# CC2753 register map
File version: 1.0
CPU: CM0+ r0p4, little endian, no MPU, no FPU, VTOR, 3 interrupt priority bits
Registers are 32-bit, read-write, reset 0x0 unless marked. A register's access mark holds for its fields unless they carry their own. Offsets are from the block's base; [hi:lo] are bit positions; {n}, {i} and the like mark numbered series; 'fields as' and 'values as' point back to an identical list.

## LRFDRFE32 (part 1 of 2)
Base 0x40083400
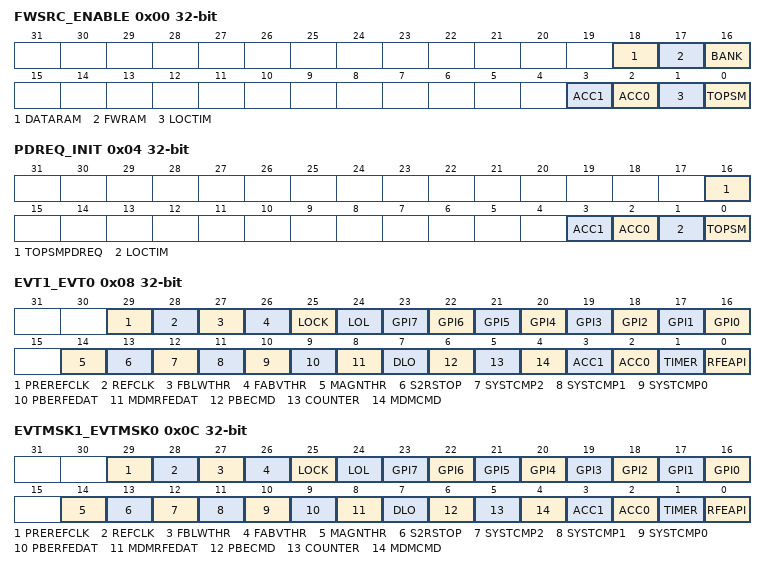
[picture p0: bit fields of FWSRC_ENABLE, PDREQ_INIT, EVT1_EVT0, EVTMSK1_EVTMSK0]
0x00 FWSRC_ENABLE — Internal. Only to be used through TI provided API.
  [18] DATARAM — Internal. Only to be used through TI provided API.
    1=S2RRAM (Internal. Only to be used through TI provided API.); 0=RFERAM (Internal. Only to be used through TI provided API.)
  [17] FWRAM — Internal. Only to be used through TI provided API.
    values as DATARAM
  [16] BANK — Internal. Only to be used through TI provided API.
    1=ONE (Internal. Only to be used through TI provided API.); 0=ZERO (Internal. Only to be used through TI provided API.)
  [3] ACC1 — Internal. Only to be used through TI provided API.
    1=EN (Internal. Only to be used through TI provided API.); 0=DIS (Internal. Only to be used through TI provided API.)
  [2] ACC0 — Internal. Only to be used through TI provided API.
    values as ACC1
  [1] LOCTIM — Internal. Only to be used through TI provided API.
    values as ACC1
  [0] TOPSM — Internal. Only to be used through TI provided API.
    values as ACC1
0x04 PDREQ_INIT wo — Internal. Only to be used through TI provided API.
  [16] TOPSMPDREQ — Internal. Only to be used through TI provided API.
    values as FWSRC_ENABLE.BANK
  [3] ACC1 — Internal. Only to be used through TI provided API.
    1=RESET (Internal. Only to be used through TI provided API.); 0=NO_EFFECT (Internal. Only to be used through TI provided API.)
  [2] ACC0 — Internal. Only to be used through TI provided API.
    values as ACC1
  [1] LOCTIM — Internal. Only to be used through TI provided API.
    values as ACC1
  [0] TOPSM — Internal. Only to be used through TI provided API.
    values as ACC1
0x08 EVT1_EVT0 ro — Internal. Only to be used through TI provided API.
  [all] fields
    values as FWSRC_ENABLE.BANK
  [29] PREREFCLK — Internal. Only to be used through TI provided API.
  [28] REFCLK — Internal. Only to be used through TI provided API.
  [27] FBLWTHR — Internal. Only to be used through TI provided API.
  [26] FABVTHR — Internal. Only to be used through TI provided API.
  [25] LOCK — Internal. Only to be used through TI provided API.
  [24] LOL — Internal. Only to be used through TI provided API.
  [n+16] GPI{n} (n=0..7) — Internal. Only to be used through TI provided API.
  [14] MAGNTHR — Internal. Only to be used through TI provided API.
  [13] S2RSTOP — Internal. Only to be used through TI provided API.
  [12] SYSTCMP2 — Internal. Only to be used through TI provided API.
  [11] SYSTCMP1 — Internal. Only to be used through TI provided API.
  [10] SYSTCMP0 — Internal. Only to be used through TI provided API.
  [9] PBERFEDAT — Internal. Only to be used through TI provided API.
  [8] MDMRFEDAT — Internal. Only to be used through TI provided API.
  [7] DLO — Internal. Only to be used through TI provided API.
  [6] PBECMD — Internal. Only to be used through TI provided API.
  [5] COUNTER — Internal. Only to be used through TI provided API.
  [4] MDMCMD — Internal. Only to be used through TI provided API.
  [3] ACC1 — Internal. Only to be used through TI provided API.
  [2] ACC0 — Internal. Only to be used through TI provided API.
  [1] TIMER — Internal. Only to be used through TI provided API.
  [0] RFEAPI — Internal. Only to be used through TI provided API.
0x0C EVTMSK1_EVTMSK0 — Internal. Only to be used through TI provided API.
  [all] fields
    values as FWSRC_ENABLE.ACC1
  [29] PREREFCLK — Internal. Only to be used through TI provided API.
  [28] REFCLK — Internal. Only to be used through TI provided API.
  [27] FBLWTHR — Internal. Only to be used through TI provided API.
  [26] FABVTHR — Internal. Only to be used through TI provided API.
  [25] LOCK — Internal. Only to be used through TI provided API.
  [24] LOL — Internal. Only to be used through TI provided API.
  [n+16] GPI{n} (n=0..7) — Internal. Only to be used through TI provided API.
  [14] MAGNTHR — Internal. Only to be used through TI provided API.
  [13] S2RSTOP — Internal. Only to be used through TI provided API.
  [12] SYSTCMP2 — Internal. Only to be used through TI provided API.
  [11] SYSTCMP1 — Internal. Only to be used through TI provided API.
  [10] SYSTCMP0 — Internal. Only to be used through TI provided API.
  [9] PBERFEDAT — Internal. Only to be used through TI provided API.
  [8] MDMRFEDAT — Internal. Only to be used through TI provided API.
  [7] DLO — Internal. Only to be used through TI provided API.
  [6] PBECMD — Internal. Only to be used through TI provided API.
  [5] COUNTER — Internal. Only to be used through TI provided API.
  [4] MDMCMD — Internal. Only to be used through TI provided API.
  [3] ACC1 — Internal. Only to be used through TI provided API.
  [2] ACC0 — Internal. Only to be used through TI provided API.
  [1] TIMER — Internal. Only to be used through TI provided API.
  [0] RFEAPI — Internal. Only to be used through TI provided API.
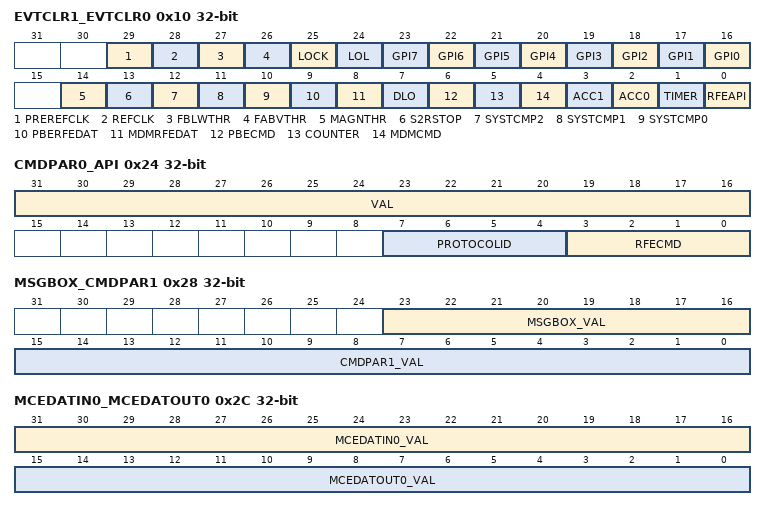
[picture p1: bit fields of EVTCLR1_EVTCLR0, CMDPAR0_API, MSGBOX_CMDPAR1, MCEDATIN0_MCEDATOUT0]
0x10 EVTCLR1_EVTCLR0 wo — Internal. Only to be used through TI provided API.
  fields as EVT1_EVT0
0x14 HFXTSTAT ro — Internal. Only to be used through TI provided API.
  [0] STAT
    1=QUAL (Internal. Only to be used through TI provided API.); 0=NONQUAL (Internal. Only to be used through TI provided API.)
0x18 RFSTATE — Internal. Only to be used through TI provided API.
  [3:0] VAL
    3=RX (Internal. Only to be used through TI provided API.); 2=TX (Internal. Only to be used through TI provided API.); 1=SYNTH (Internal. Only to be used through TI provided API.); 0=IDLE (Internal. Only to be used through TI provided API.)
0x24 CMDPAR0_API ro — Internal. Only to be used through TI provided API.
  [31:16] VAL — Internal. Only to be used through TI provided API.
    0xFFFF=ALLONES (Internal. Only to be used through TI provided API.); 0=ALLZEROS (Internal. Only to be used through TI provided API.)
  [7:4] PROTOCOLID — Internal. Only to be used through TI provided API.
    15=ALLONES (Internal. Only to be used through TI provided API.); 0=ALLZEROS (Internal. Only to be used through TI provided API.)
  [3:0] RFECMD — Internal. Only to be used through TI provided API.
    values as PROTOCOLID
0x28 MSGBOX_CMDPAR1 ro — Internal. Only to be used through TI provided API.
  [23:16] MSGBOX_VAL — Internal. Only to be used through TI provided API.
    255=ALLONES (Internal. Only to be used through TI provided API.); 0=ALLZEROS (Internal. Only to be used through TI provided API.)
  [15:0] CMDPAR1_VAL — Internal. Only to be used through TI provided API.
    values as CMDPAR0_API.VAL
0x2C MCEDATIN0_MCEDATOUT0 — Internal. Only to be used through TI provided API.
  [31:16] MCEDATIN0_VAL ro — Internal. Only to be used through TI provided API.
    values as CMDPAR0_API.VAL
  [15:0] MCEDATOUT0_VAL — Internal. Only to be used through TI provided API.
    values as CMDPAR0_API.VAL
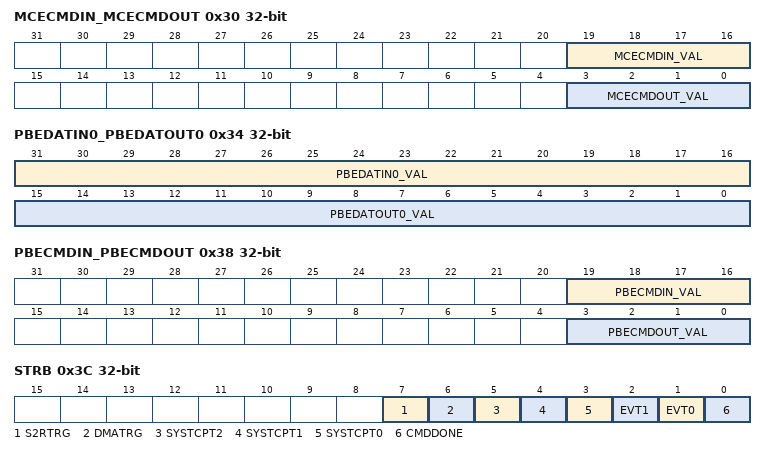
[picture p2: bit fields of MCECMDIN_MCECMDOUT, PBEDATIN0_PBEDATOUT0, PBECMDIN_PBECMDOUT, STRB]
0x30 MCECMDIN_MCECMDOUT — Internal. Only to be used through TI provided API.
  [19:16] MCECMDIN_VAL ro — Internal. Only to be used through TI provided API.
    values as CMDPAR0_API.PROTOCOLID
  [3:0] MCECMDOUT_VAL — Internal. Only to be used through TI provided API.
    values as CMDPAR0_API.PROTOCOLID
0x34 PBEDATIN0_PBEDATOUT0 — Internal. Only to be used through TI provided API.
  [31:16] PBEDATIN0_VAL ro — Internal. Only to be used through TI provided API.
    values as CMDPAR0_API.VAL
  [15:0] PBEDATOUT0_VAL — Internal. Only to be used through TI provided API.
    values as CMDPAR0_API.VAL
0x38 PBECMDIN_PBECMDOUT — Internal. Only to be used through TI provided API.
  [19:16] PBECMDIN_VAL ro — Internal. Only to be used through TI provided API.
    values as CMDPAR0_API.PROTOCOLID
  [3:0] PBECMDOUT_VAL — Internal. Only to be used through TI provided API.
    values as CMDPAR0_API.PROTOCOLID
0x3C STRB wo — Internal. Only to be used through TI provided API.
  [7] S2RTRG — Internal. Only to be used through TI provided API.
    values as FWSRC_ENABLE.BANK
  [6] DMATRG — Internal. Only to be used through TI provided API.
    values as FWSRC_ENABLE.BANK
  [5] SYSTCPT2 — Internal. Only to be used through TI provided API.
    values as FWSRC_ENABLE.BANK
  [4] SYSTCPT1 — Internal. Only to be used through TI provided API.
    values as FWSRC_ENABLE.BANK
  [3] SYSTCPT0 — Internal. Only to be used through TI provided API.
    values as FWSRC_ENABLE.BANK
  [2] EVT1 — Internal. Only to be used through TI provided API.
    values as FWSRC_ENABLE.BANK
  [1] EVT0 — Internal. Only to be used through TI provided API.
    values as FWSRC_ENABLE.BANK
  [0] CMDDONE — Internal. Only to be used through TI provided API.
    1=YES (Internal. Only to be used through TI provided API.); 0=NO (Internal. Only to be used through TI provided API.)
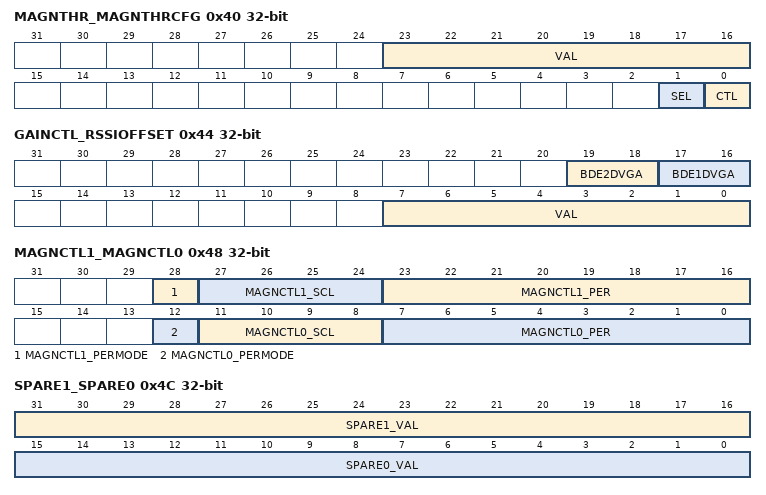
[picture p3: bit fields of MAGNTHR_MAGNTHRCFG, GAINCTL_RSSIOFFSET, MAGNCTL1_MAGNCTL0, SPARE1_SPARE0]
0x40 MAGNTHR_MAGNTHRCFG — Internal. Only to be used through TI provided API.
  [23:16] VAL — Internal. Only to be used through TI provided API.
    values as MSGBOX_CMDPAR1.MSGBOX_VAL
  [1] SEL — Internal. Only to be used through TI provided API.
    1=MAGNACC1 (Internal. Only to be used through TI provided API.); 0=MAGNACC0 (Internal. Only to be used through TI provided API.)
  [0] CTL — Internal. Only to be used through TI provided API.
    values as FWSRC_ENABLE.ACC1
0x44 GAINCTL_RSSIOFFSET — Internal. Only to be used through TI provided API.
  [19:18] BDE2DVGA — Internal. Only to be used through TI provided API.
    3=GAIN8 (Internal. Only to be used through TI provided API.); 2=GAIN4 (Internal. Only to be used through TI provided API.); 1=GAIN2 (Internal. Only to be used through TI provided API.); 0=GAIN1 (Internal. Only to be used through TI provided API.)
  [17:16] BDE1DVGA — Internal. Only to be used through TI provided API.
    values as BDE2DVGA
  [7:0] VAL — Internal. Only to be used through TI provided API.
    values as MSGBOX_CMDPAR1.MSGBOX_VAL
0x48 MAGNCTL1_MAGNCTL0 — Internal. Only to be used through TI provided API.
  [28] MAGNCTL1_PERMODE — Internal. Only to be used through TI provided API.
    1=PERIODIC (Internal. Only to be used through TI provided API.); 0=ONESHOT (Internal. Only to be used through TI provided API.)
  [27:24] MAGNCTL1_SCL — Internal. Only to be used through TI provided API.
    8=DIV256 (Internal. Only to be used through TI provided API.); 7=DIV128 (Internal. Only to be used through TI provided API.); 6=DIV64 (Internal. Only to be used through TI provided API.); 5=DIV32 (Internal. Only to be used through TI provided API.); 4=DIV16 (Internal. Only to be used through TI provided API.); 3=DIV8 (Internal. Only to be used through TI provided API.); 2=DIV4 (Internal. Only to be used through TI provided API.); 1=DIV2 (Internal. Only to be used through TI provided API.); 0=DIV1 (Internal. Only to be used through TI provided API.)
  [23:16] MAGNCTL1_PER — Internal. Only to be used through TI provided API.
    values as MSGBOX_CMDPAR1.MSGBOX_VAL
  [12] MAGNCTL0_PERMODE — Internal. Only to be used through TI provided API.
    values as MAGNCTL1_PERMODE
  [11:8] MAGNCTL0_SCL — Internal. Only to be used through TI provided API.
    values as MAGNCTL1_SCL
  [7:0] MAGNCTL0_PER — Internal. Only to be used through TI provided API.
    values as MSGBOX_CMDPAR1.MSGBOX_VAL
0x4C SPARE1_SPARE0 — Internal. Only to be used through TI provided API.
  [31:16] SPARE1_VAL — Internal. Only to be used through TI provided API.
    values as CMDPAR0_API.VAL
  [15:0] SPARE0_VAL — Internal. Only to be used through TI provided API.
    values as CMDPAR0_API.VAL
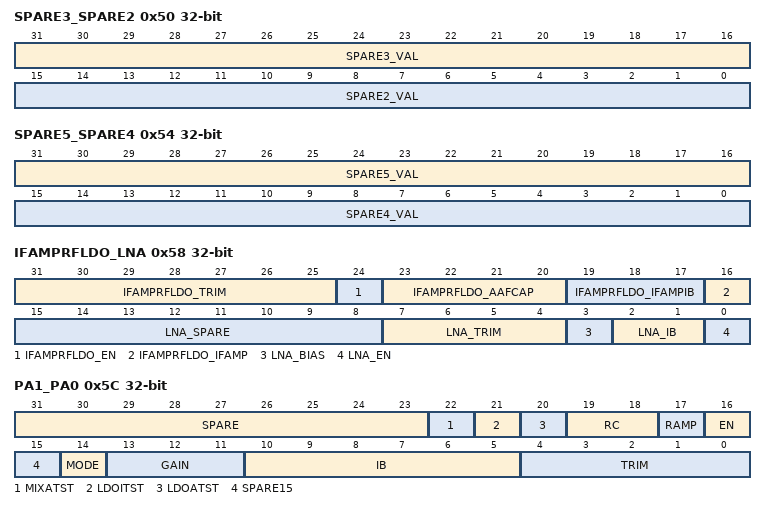
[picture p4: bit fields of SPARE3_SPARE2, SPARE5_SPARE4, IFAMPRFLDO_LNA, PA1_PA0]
0x50 SPARE3_SPARE2 — Internal. Only to be used through TI provided API.
  [31:16] SPARE3_VAL — Internal. Only to be used through TI provided API.
    values as CMDPAR0_API.VAL
  [15:0] SPARE2_VAL — Internal. Only to be used through TI provided API.
    values as CMDPAR0_API.VAL
0x54 SPARE5_SPARE4 — Internal. Only to be used through TI provided API.
  [31:16] SPARE5_VAL — Internal. Only to be used through TI provided API.
    values as CMDPAR0_API.VAL
  [15:0] SPARE4_VAL — Internal. Only to be used through TI provided API.
    values as CMDPAR0_API.VAL
0x58 IFAMPRFLDO_LNA — Internal. Only to be used through TI provided API.
  [31:25] IFAMPRFLDO_TRIM — Internal. Only to be used through TI provided API.
    127=BYPASS (Internal. Only to be used through TI provided API.); 126=MAX (Internal. Only to be used through TI provided API.); 0=MIN (Internal. Only to be used through TI provided API.)
  [24] IFAMPRFLDO_EN — Internal. Only to be used through TI provided API.
    values as FWSRC_ENABLE.ACC1
  [23:20] IFAMPRFLDO_AAFCAP — Internal. Only to be used through TI provided API.
    15=MAX (Internal. Only to be used through TI provided API.); 0=MIN (Internal. Only to be used through TI provided API.)
  [19:17] IFAMPRFLDO_IFAMPIB — Internal. Only to be used through TI provided API.
    7=MAX (Internal. Only to be used through TI provided API.); 0=MIN (Internal. Only to be used through TI provided API.)
  [16] IFAMPRFLDO_IFAMP — Internal. Only to be used through TI provided API.
    values as FWSRC_ENABLE.ACC1
  [15:8] LNA_SPARE — Internal. Only to be used through TI provided API.
    values as FWSRC_ENABLE.ACC1
  [7:4] LNA_TRIM — Internal. Only to be used through TI provided API.
    15=ONES (Internal. Only to be used through TI provided API.); 0=ZEROS (Internal. Only to be used through TI provided API.)
  [3] LNA_BIAS — Internal. Only to be used through TI provided API.
    1=INT (Internal. Only to be used through TI provided API.); 0=BGAP (Internal. Only to be used through TI provided API.)
  [2:1] LNA_IB — Internal. Only to be used through TI provided API.
    3=MAX (Internal. Only to be used through TI provided API.); 0=MIN (Internal. Only to be used through TI provided API.)
  [0] LNA_EN — Internal. Only to be used through TI provided API.
    1=ON (Internal. Only to be used through TI provided API.); 0=OFF (Internal. Only to be used through TI provided API.)
0x5C PA1_PA0 — Internal. Only to be used through TI provided API.
  [31:23] SPARE — Internal. Only to be used through TI provided API.
    values as IFAMPRFLDO_LNA.LNA_IB
  [22] MIXATST — Internal. Only to be used through TI provided API.
    values as FWSRC_ENABLE.ACC1
  [21] LDOITST — Internal. Only to be used through TI provided API.
    values as FWSRC_ENABLE.ACC1
  [20] LDOATST — Internal. Only to be used through TI provided API.
    values as FWSRC_ENABLE.ACC1
  [19:18] RC — Internal. Only to be used through TI provided API.
    values as IFAMPRFLDO_LNA.LNA_IB
  [17] RAMP — Internal. Only to be used through TI provided API.
    1=UP (Internal. Only to be used through TI provided API.); 0=DOWN (Internal. Only to be used through TI provided API.)
  [16] EN — Internal. Only to be used through TI provided API.
    values as FWSRC_ENABLE.ACC1
  [15] SPARE15 — Internal. Only to be used through TI provided API.
    values as FWSRC_ENABLE.BANK
  [14] MODE — Internal. Only to be used through TI provided API.
    1=HIGH (Internal. Only to be used through TI provided API.); 0=LOW (Internal. Only to be used through TI provided API.)
  [13:11] GAIN — Internal. Only to be used through TI provided API.
    values as IFAMPRFLDO_LNA.IFAMPRFLDO_IFAMPIB
  [10:5] IB — Internal. Only to be used through TI provided API.
    63=MAX (Internal. Only to be used through TI provided API.); 0=MIN (Internal. Only to be used through TI provided API.)
  [4:0] TRIM — Internal. Only to be used through TI provided API.
    31=MAX (Internal. Only to be used through TI provided API.); 0=MIN (Internal. Only to be used through TI provided API.)
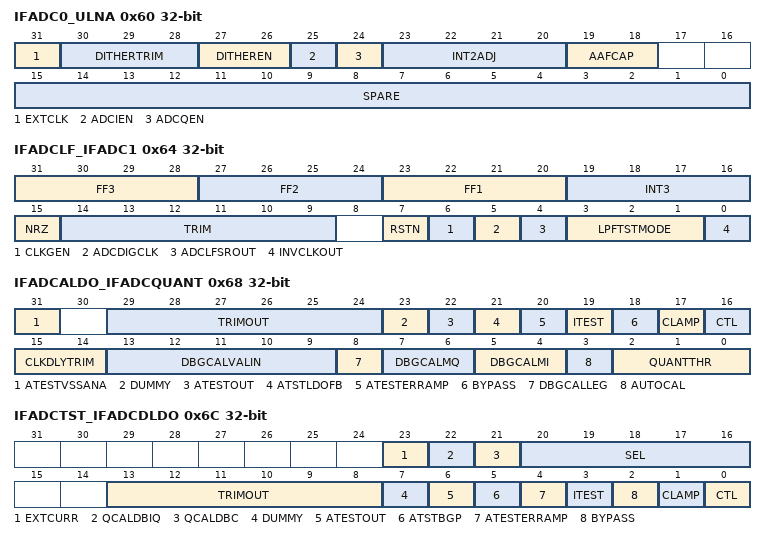
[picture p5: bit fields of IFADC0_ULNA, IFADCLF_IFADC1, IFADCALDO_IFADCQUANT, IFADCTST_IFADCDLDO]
0x60 IFADC0_ULNA — Internal. Only to be used through TI provided API.
  [31] EXTCLK — Internal. Only to be used through TI provided API.
    values as FWSRC_ENABLE.ACC1
  [30:28] DITHERTRIM — Internal. Only to be used through TI provided API.
    7=ONES (Internal. Only to be used through TI provided API.); 0=ZEROS (Internal. Only to be used through TI provided API.)
  [27:26] DITHEREN — Internal. Only to be used through TI provided API.
    3=ENG (Internal. Only to be used through TI provided API.); 2=ENSD (Internal. Only to be used through TI provided API.); 1=ENS (Internal. Only to be used through TI provided API.); 0=DIS (Internal. Only to be used through TI provided API.)
  [25] ADCIEN — Internal. Only to be used through TI provided API.
    values as FWSRC_ENABLE.ACC1
  [24] ADCQEN — Internal. Only to be used through TI provided API.
    values as FWSRC_ENABLE.ACC1
  [23:20] INT2ADJ — Internal. Only to be used through TI provided API.
    values as IFAMPRFLDO_LNA.LNA_TRIM
  [19:18] AAFCAP — Internal. Only to be used through TI provided API.
    values as DITHEREN
  [15:0] SPARE — Internal. Only to be used through TI provided API.
    values as CMDPAR0_API.VAL
0x64 IFADCLF_IFADC1 — Internal. Only to be used through TI provided API.
  [31:28] FF3 — Internal. Only to be used through TI provided API.
    values as IFAMPRFLDO_LNA.LNA_TRIM
  [27:24] FF2 — Internal. Only to be used through TI provided API.
    values as IFAMPRFLDO_LNA.LNA_TRIM
  [23:20] FF1 — Internal. Only to be used through TI provided API.
    values as IFAMPRFLDO_LNA.LNA_TRIM
  [19:16] INT3 — Internal. Only to be used through TI provided API.
    values as IFAMPRFLDO_LNA.LNA_TRIM
  [15] NRZ — Internal. Only to be used through TI provided API.
    values as FWSRC_ENABLE.ACC1
  [14:9] TRIM — Internal. Only to be used through TI provided API.
    63=ONES (Internal. Only to be used through TI provided API.); 0=ZEROS (Internal. Only to be used through TI provided API.)
  [7] RSTN — Internal. Only to be used through TI provided API.
    1=DIS (Internal. Only to be used through TI provided API.); 0=EN (Internal. Only to be used through TI provided API.)
  [6] CLKGEN — Internal. Only to be used through TI provided API.
    values as FWSRC_ENABLE.ACC1
  [5] ADCDIGCLK — Internal. Only to be used through TI provided API.
    values as FWSRC_ENABLE.ACC1
  [4] ADCLFSROUT — Internal. Only to be used through TI provided API.
    values as FWSRC_ENABLE.ACC1
  [3:1] LPFTSTMODE — Internal. Only to be used through TI provided API.
    values as FWSRC_ENABLE.ACC1
  [0] INVCLKOUT — Internal. Only to be used through TI provided API.
    values as FWSRC_ENABLE.ACC1
0x68 IFADCALDO_IFADCQUANT — Internal. Only to be used through TI provided API.
  [31] ATESTVSSANA — Internal. Only to be used through TI provided API.
    values as FWSRC_ENABLE.ACC1
  [29:24] TRIMOUT — Internal. Only to be used through TI provided API.
    values as IFADCLF_IFADC1.TRIM
  [23] DUMMY — Internal. Only to be used through TI provided API.
    values as FWSRC_ENABLE.ACC1
  [22] ATESTOUT — Internal. Only to be used through TI provided API.
    values as FWSRC_ENABLE.ACC1
  [21] ATSTLDOFB — Internal. Only to be used through TI provided API.
    values as FWSRC_ENABLE.ACC1
  [20] ATESTERRAMP — Internal. Only to be used through TI provided API.
    values as FWSRC_ENABLE.ACC1
  [19] ITEST — Internal. Only to be used through TI provided API.
    values as FWSRC_ENABLE.ACC1
  [18] BYPASS — Internal. Only to be used through TI provided API.
    values as FWSRC_ENABLE.ACC1
  [17] CLAMP — Internal. Only to be used through TI provided API.
    values as FWSRC_ENABLE.ACC1
  [16] CTL — Internal. Only to be used through TI provided API.
    values as FWSRC_ENABLE.ACC1
  [15:14] CLKDLYTRIM — Internal. Only to be used through TI provided API.
    3=ONES (Internal. Only to be used through TI provided API.); 0=ZEROS (Internal. Only to be used through TI provided API.)
  [13:9] DBGCALVALIN — Internal. Only to be used through TI provided API.
    31=ONES (Internal. Only to be used through TI provided API.); 0=ZEROS (Internal. Only to be used through TI provided API.)
  [8] DBGCALLEG — Internal. Only to be used through TI provided API.
    1=NEG (Internal. Only to be used through TI provided API.); 0=POS (Internal. Only to be used through TI provided API.)
  [7:6] DBGCALMQ — Internal. Only to be used through TI provided API.
    3=DBGCAL_QMODB (Internal. Only to be used through TI provided API.); 2=DBGCAL_QMODP (Internal. Only to be used through TI provided API.); 1=DBGCAL_QMODN (Internal. Only to be used through TI provided API.); 0=DBGCAL_QMODZ (Internal. Only to be used through TI provided API.)
  [5:4] DBGCALMI — Internal. Only to be used through TI provided API.
    3=DBGCAL_IMODB (Internal. Only to be used through TI provided API.); 2=DBGCAL_IMODP (Internal. Only to be used through TI provided API.); 1=DBGCAL_IMODN (Internal. Only to be used through TI provided API.); 0=DBGCAL_IMODZ (Internal. Only to be used through TI provided API.)
  [3] AUTOCAL — Internal. Only to be used through TI provided API.
    values as FWSRC_ENABLE.ACC1
  [2:0] QUANTTHR — Internal. Only to be used through TI provided API.
    values as IFADC0_ULNA.DITHERTRIM
0x6C IFADCTST_IFADCDLDO — Internal. Only to be used through TI provided API.
  [23] EXTCURR — Internal. Only to be used through TI provided API.
    values as FWSRC_ENABLE.ACC1
  [22] QCALDBIQ — Internal. Only to be used through TI provided API.
    1=COMP1 (Internal. Only to be used through TI provided API.); 0=COMP0 (Internal. Only to be used through TI provided API.)
  [21] QCALDBC — Internal. Only to be used through TI provided API.
    values as QCALDBIQ
  [20:16] SEL — Internal. Only to be used through TI provided API.
    31=EXTCLKN1 (Internal. Only to be used through TI provided API.); 0=NONE (Internal. Only to be used through TI provided API.)
  [13:8] TRIMOUT — Internal. Only to be used through TI provided API.
    values as IFADCLF_IFADC1.TRIM
  [7] DUMMY — Internal. Only to be used through TI provided API.
    values as FWSRC_ENABLE.ACC1
  [6] ATESTOUT — Internal. Only to be used through TI provided API.
    values as FWSRC_ENABLE.ACC1
  [5] ATSTBGP — Internal. Only to be used through TI provided API.
    values as FWSRC_ENABLE.ACC1
  [4] ATESTERRAMP — Internal. Only to be used through TI provided API.
    values as FWSRC_ENABLE.ACC1
  [3] ITEST — Internal. Only to be used through TI provided API.
    values as FWSRC_ENABLE.ACC1
  [2] BYPASS — Internal. Only to be used through TI provided API.
    values as FWSRC_ENABLE.ACC1
  [1] CLAMP — Internal. Only to be used through TI provided API.
    values as FWSRC_ENABLE.ACC1
  [0] CTL — Internal. Only to be used through TI provided API.
    values as FWSRC_ENABLE.ACC1
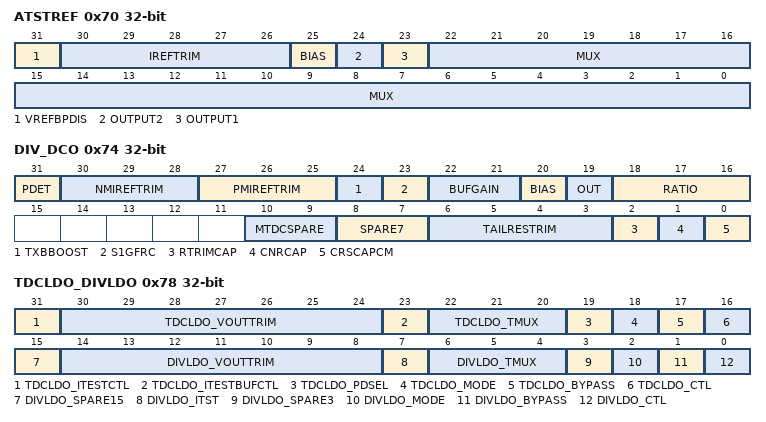
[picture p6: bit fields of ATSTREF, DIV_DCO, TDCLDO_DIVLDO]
0x70 ATSTREF — Internal. Only to be used through TI provided API.
  [31] VREFBPDIS — Internal. Only to be used through TI provided API.
    1=BPDIS (Internal. Only to be used through TI provided API.); 0=BPEN (Internal. Only to be used through TI provided API.)
  [30:26] IREFTRIM — Internal. Only to be used through TI provided API.
    values as IFADCALDO_IFADCQUANT.DBGCALVALIN
  [25] BIAS — Internal. Only to be used through TI provided API.
    values as FWSRC_ENABLE.ACC1
  [24] OUTPUT2 — Internal. Only to be used through TI provided API.
    values as FWSRC_ENABLE.ACC1
  [23] OUTPUT1 — Internal. Only to be used through TI provided API.
    values as FWSRC_ENABLE.ACC1
  [22:0] MUX — Internal. Only to be used through TI provided API.
    0x8000=IFADC_ATB (Internal. Only to be used through TI provided API.); 0x4000=LDO_VTEST (Internal. Only to be used through TI provided API.); 0x2000=LDO_ITEST (Internal. Only to be used through TI provided API.); 0x800=PA_PEAK_OUTN (Internal. Only to be used through TI provided API.); 0x400=PA_PEAK_OUTP (Internal. Only to be used through TI provided API.); 0x200=MIX_OUTQN (Internal. Only to be used through TI provided API.); 0x100=MIX_OUTQP (Internal. Only to be used through TI provided API.); 128=MIX_OUTIN (Internal. Only to be used through TI provided API.); 64=MIX_OUTIP (Internal. Only to be used through TI provided API.); 32=FE_OUTIN_2 (Internal. Only to be used through TI provided API.); 16=FE_OUTIP_2 (Internal. Only to be used through TI provided API.); 8=FE_OUTQN (Internal. Only to be used through TI provided API.); 4=FE_OUTQP (Internal. Only to be used through TI provided API.); 2=FE_OUTIN (Internal. Only to be used through TI provided API.); 1=FE_OUTIP (Internal. Only to be used through TI provided API.); 0=DIS (Internal. Only to be used through TI provided API.)
0x74 DIV_DCO — Internal. Only to be used through TI provided API.
  [31] PDET — Internal. Only to be used through TI provided API.
    values as FWSRC_ENABLE.ACC1
  [30:28] NMIREFTRIM — Internal. Only to be used through TI provided API.
    7=ALLONES (Internal. Only to be used through TI provided API.); 0=ALLZEROS (Internal. Only to be used through TI provided API.)
  [27:25] PMIREFTRIM — Internal. Only to be used through TI provided API.
    values as NMIREFTRIM
  [24] TXBBOOST — Internal. Only to be used through TI provided API.
    1=INCREASED (Internal. Only to be used through TI provided API.); 0=DEFAULT (Internal. Only to be used through TI provided API.)
  [23] S1GFRC — Internal. Only to be used through TI provided API.
    values as FWSRC_ENABLE.ACC1
  [22:21] BUFGAIN — Internal. Only to be used through TI provided API.
    3=_60_PST (Internal. Only to be used through TI provided API.); 2=DONT_USE (Internal. Only to be used through TI provided API.); 1=_80_PST (Internal. Only to be used through TI provided API.); 0=MAX (Internal. Only to be used through TI provided API.)
  [20] BIAS — Internal. Only to be used through TI provided API.
    1=DEFAULT (Internal. Only to be used through TI provided API.); 0=ALTERNATIVE (Internal. Only to be used through TI provided API.)
  [19] OUT — Internal. Only to be used through TI provided API.
    1=FE_2G4 (Internal. Only to be used through TI provided API.); 0=FE_S1G (Internal. Only to be used through TI provided API.)
  [18:16] RATIO — Internal. Only to be used through TI provided API.
    7=DIV30 (Internal. Only to be used through TI provided API.); 6=DIV15 (Internal. Only to be used through TI provided API.); 5=DIV10 (Internal. Only to be used through TI provided API.); 4=DIV5 (Internal. Only to be used through TI provided API.); 3=DIV12 (Internal. Only to be used through TI provided API.); 2=DIV6 (Internal. Only to be used through TI provided API.); 1=DIV4 (Internal. Only to be used through TI provided API.); 0=DIV2 (Internal. Only to be used through TI provided API.)
  [10:9] MTDCSPARE — Internal. Only to be used through TI provided API.
    values as IFADCLF_IFADC1.RSTN
  [8:7] SPARE7 — Internal. Only to be used through TI provided API.
    values as FWSRC_ENABLE.BANK
  [6:3] TAILRESTRIM — Internal. Only to be used through TI provided API.
    values as CMDPAR0_API.PROTOCOLID
  [2] RTRIMCAP — Internal. Only to be used through TI provided API.
    values as FWSRC_ENABLE.ACC1
  [1] CNRCAP — Internal. Only to be used through TI provided API.
    1=_50MHZ (Internal. Only to be used through TI provided API.); 0=DEFAULT (Internal. Only to be used through TI provided API.)
  [0] CRSCAPCM — Internal. Only to be used through TI provided API.
    1=REDUCED (Internal. Only to be used through TI provided API.); 0=DEFAULT (Internal. Only to be used through TI provided API.)
0x78 TDCLDO_DIVLDO — Internal. Only to be used through TI provided API.
  [31] TDCLDO_ITESTCTL — Internal. Only to be used through TI provided API.
    values as FWSRC_ENABLE.ACC1
  [30:24] TDCLDO_VOUTTRIM — Internal. Only to be used through TI provided API.
    127=ONES (Internal. Only to be used through TI provided API.); 0=ZEROS (Internal. Only to be used through TI provided API.)
  [23] TDCLDO_ITESTBUFCTL — Internal. Only to be used through TI provided API.
    values as FWSRC_ENABLE.ACC1
  [22:20] TDCLDO_TMUX — Internal. Only to be used through TI provided API.
    4=VSSA (Internal. Only to be used through TI provided API.); 2=LDO_OUT (Internal. Only to be used through TI provided API.); 1=VDDA (Internal. Only to be used through TI provided API.); 0=OFF (Internal. Only to be used through TI provided API.)
  [19] TDCLDO_PDSEL — Internal. Only to be used through TI provided API.
    1=DIODE (Internal. Only to be used through TI provided API.); 0=R (Internal. Only to be used through TI provided API.)
  [18] TDCLDO_MODE — Internal. Only to be used through TI provided API.
    1=FAST (Internal. Only to be used through TI provided API.); 0=NORM (Internal. Only to be used through TI provided API.)
  [17] TDCLDO_BYPASS — Internal. Only to be used through TI provided API.
    values as FWSRC_ENABLE.ACC1
  [16] TDCLDO_CTL — Internal. Only to be used through TI provided API.
    values as FWSRC_ENABLE.ACC1
  [15] DIVLDO_SPARE15 — Internal. Only to be used through TI provided API.
    1=ONES (Internal. Only to be used through TI provided API.); 0=ZEROS (Internal. Only to be used through TI provided API.)
  [14:8] DIVLDO_VOUTTRIM — Internal. Only to be used through TI provided API.
    values as TDCLDO_VOUTTRIM
  [7] DIVLDO_ITST — Internal. Only to be used through TI provided API.
    values as FWSRC_ENABLE.ACC1
  [6:4] DIVLDO_TMUX — Internal. Only to be used through TI provided API.
    4=VDDR (Internal. Only to be used through TI provided API.); 2=LDO_OUT (Internal. Only to be used through TI provided API.); 1=GND (Internal. Only to be used through TI provided API.); 0=OFF (Internal. Only to be used through TI provided API.)
  [3] DIVLDO_SPARE3 — Internal. Only to be used through TI provided API.
    values as FWSRC_ENABLE.BANK
  [2] DIVLDO_MODE — Internal. Only to be used through TI provided API.
    values as TDCLDO_MODE
  [1] DIVLDO_BYPASS — Internal. Only to be used through TI provided API.
    values as FWSRC_ENABLE.ACC1
  [0] DIVLDO_CTL — Internal. Only to be used through TI provided API.
    values as FWSRC_ENABLE.ACC1
